# FM33L0XXD register map
File version: 1.0
CPU: SC000 r1p0, little endian, no MPU, FPU, 8 interrupt priority bits
Registers are 32-bit, read-write, reset 0x0 unless marked. A register's access mark holds for its fields unless they carry their own. Offsets are from the block's base; [hi:lo] are bit positions; {n}, {i} and the like mark numbered series.

## SARADC — SARADC module information
Base 0x40015000
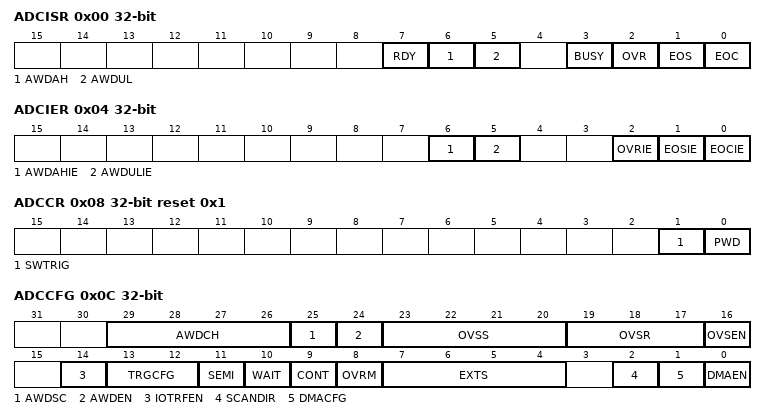
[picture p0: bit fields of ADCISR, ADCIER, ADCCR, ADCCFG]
0x00 ADCISR
  [7] RDY ro — RDY field description
  [6] AWDAH — AWD_AH field description
  [5] AWDUL — AWD_UL field description
  [3] BUSY ro — BUSY field description
  [2] OVR — OVR field description
  [1] EOS — EOS field description
  [0] EOC — EOC field description
0x04 ADCIER
  [6] AWDAHIE — AWD_AHIE field description
  [5] AWDULIE — AWD_ULIE field description
  [2] OVRIE — OVRIE field description
  [1] EOSIE — EOSIE field description
  [0] EOCIE — EOCIE field description
0x08 ADCCR reset 0x1
  [1] SWTRIG — SWTRIG field description
  [0] PWD — PWD field description
0x0C ADCCFG
  [29:26] AWDCH — AWDCH field description
  [25] AWDSC — AWDSC field description
  [24] AWDEN — AWDEN field description
  [23:20] OVSS — OVSS field description
  [19:17] OVSR — OVSR field description
  [16] OVSEN — OVSEN field description
  [14] IOTRFEN — IOTRFEN field description
  [13:12] TRGCFG — TRGCFG field description
  [11] SEMI — SEMI field description
  [10] WAIT — WAIT field description
  [9] CONT — CONT field description
  [8] OVRM — OVRM field description
  [7:4] EXTS — EXTS field description
  [2] SCANDIR — SCANDIR field description
  [1] DMACFG — DMACFG field description
  [0] DMAEN — DMAEN field description
0x10 ADCSMTR
  [3:0] SMTR1 — SMTR1 field description
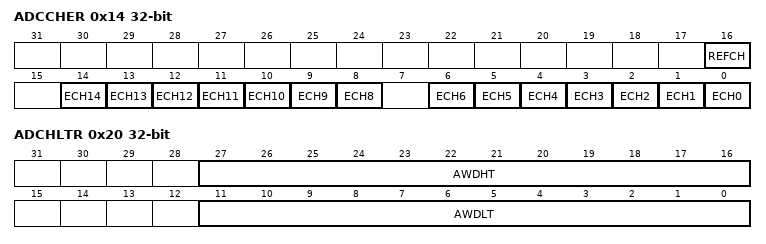
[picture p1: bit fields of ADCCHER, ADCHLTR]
0x14 ADCCHER
  [16] REFCH — REFCH field description
  [n] ECH{n} (n=8..14) — ECH{n} field description
  [n] ECH{n} (n=0..6) — ECH{n} field description
0x18 ADCDR
  [15:0] DATA ro — DATA field description
0x20 ADCHLTR
  [27:16] AWDHT — AWD_HT field description
  [11:0] AWDLT — AWD_LT field description

## SDADC — SDADC module information
Base 0x40012828
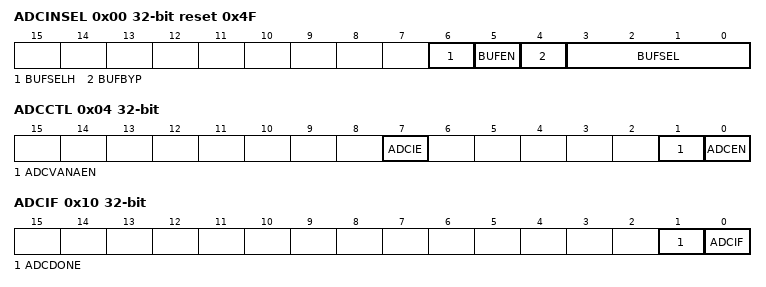
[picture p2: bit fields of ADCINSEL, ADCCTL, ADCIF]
0x00 ADCINSEL reset 0x4F
  [6] BUFSELH — BUFSELH field description
  [5] BUFEN — BUFEN field description
  [4] BUFBYP — BUFBYP field description
  [3:0] BUFSEL — BUFSEL field description
0x04 ADCCTL
  [7] ADCIE — ADC_IE field description
  [1] ADCVANAEN — ADC_VANA_EN field description
  [0] ADCEN — ADC_EN field description
0x08 ADCTRIM
  [10:0] ADCTRIM — ADC_TRIM field description
0x0C ADCDATA
  [10:0] ADCDATA ro — ADC_DATA field description
0x10 ADCIF
  [1] ADCDONE ro — ADC_DONE field description
  [0] ADCIF — ADC_IF field description

## SPI0 — SPI0 module information
Base 0x40000800
Same registers: SPI1 0x40000840, SPI2 0x40000880
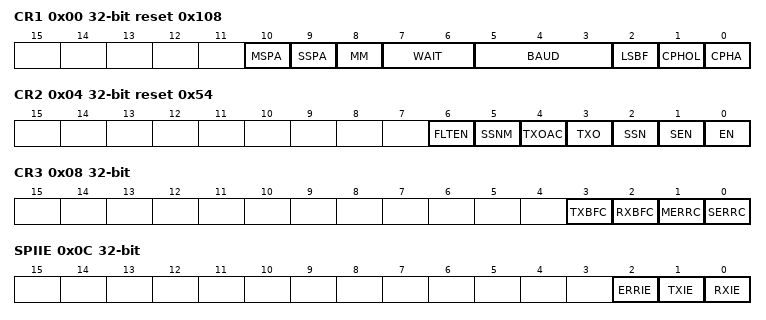
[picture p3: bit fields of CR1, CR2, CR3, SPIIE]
0x00 CR1 reset 0x108
  [10] MSPA — MSPA field description
  [9] SSPA — SSPA field description
  [8] MM — MM field description
  [7:6] WAIT — WAIT field description
  [5:3] BAUD — BAUD field description
  [2] LSBF — LSBF field description
  [1] CPHOL — CPHOL field description
  [0] CPHA — CPHA field description
0x04 CR2 reset 0x54
  [6] FLTEN — FLTEN field description
  [5] SSNM — SSNM field description
  [4] TXOAC — TXO_AC field description
  [3] TXO — TXO field description
  [2] SSN — SSN field description
  [1] SEN — SEN field description
  [0] EN — EN field description
0x08 CR3
  [3] TXBFC — TXBFC field description
  [2] RXBFC — RXBFC field description
  [1] MERRC — MERRC field description
  [0] SERRC — SERRC field description
0x0C SPIIE
  [2] ERRIE — ERRIE field description
  [1] TXIE — TXIE field description
  [0] RXIE — RXIE field description
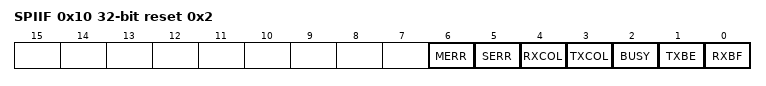
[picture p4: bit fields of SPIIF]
0x10 SPIIF reset 0x2
  [6] MERR ro — MERR field description
  [5] SERR ro — SERR field description
  [4] RXCOL — RXCOL field description
  [3] TXCOL — TXCOL field description
  [2] BUSY ro — BUSY field description
  [1] TXBE ro — TXBE field description
  [0] RXBF ro — RXBF field description
0x14 TXBUF
  [7:0] TXBUF wo — TXBUF field description
0x18 RXBUF
  [7:0] RXBUF ro — RXBUF field description

## SVD — SVD module information
Base 0x40012800
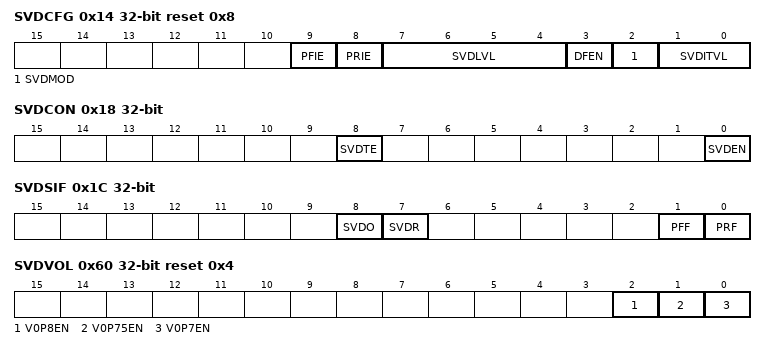
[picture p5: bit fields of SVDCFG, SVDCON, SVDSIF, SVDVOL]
0x14 SVDCFG reset 0x8
  [9] PFIE — PFIE field description
  [8] PRIE — PRIE field description
  [7:4] SVDLVL — SVDLVL field description
  [3] DFEN — DFEN field description
  [2] SVDMOD — SVDMOD field description
  [1:0] SVDITVL — SVDITVL field description
0x18 SVDCON
  [8] SVDTE — SVDTE field description
  [0] SVDEN — SVDEN field description
0x1C SVDSIF
  [8] SVDO ro — SVDO field description
  [7] SVDR ro — SVDR field description
  [1] PFF — PFF field description
  [0] PRF — PRF field description
0x60 SVDVOL reset 0x4
  [2] V0P8EN — V0P8EN field description
  [1] V0P75EN — V0P75EN field description
  [0] V0P7EN — V0P7EN field description
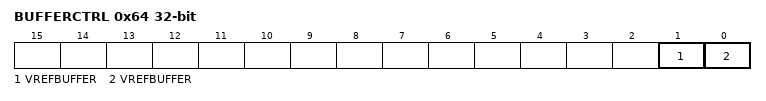
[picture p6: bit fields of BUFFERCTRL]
0x64 BUFFERCTRL
  [1] VREFBUFFER OUTEN — VREFBUFFER _OUTEN field description
  [0] VREFBUFFER EN — VREFBUFFER _EN field description
